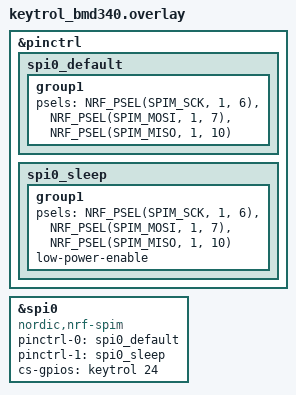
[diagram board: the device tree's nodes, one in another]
&pinctrl {

    spi0_default: spi0_default {
        group1 {
            psels = <NRF_PSEL(SPIM_SCK, 1, 6)>,
                    <NRF_PSEL(SPIM_MOSI, 1, 7)>,
                    <NRF_PSEL(SPIM_MISO, 1, 10)>;
        };
    };

    spi0_sleep: spi0_sleep {
        group1 {
            psels = <NRF_PSEL(SPIM_SCK, 1, 6)>,
                    <NRF_PSEL(SPIM_MOSI, 1, 7)>,
                    <NRF_PSEL(SPIM_MISO, 1, 10)>;
            low-power-enable;
        };
    };
};

nice_view_spi: &spi0 {
    compatible = "nordic,nrf-spim";
    status = "okay";

    pinctrl-0 = <&spi0_default>;
    pinctrl-1 = <&spi0_sleep>;
    pinctrl-names = "default", "sleep";
    cs-gpios = <&keytrol 24 GPIO_ACTIVE_HIGH>;

};
